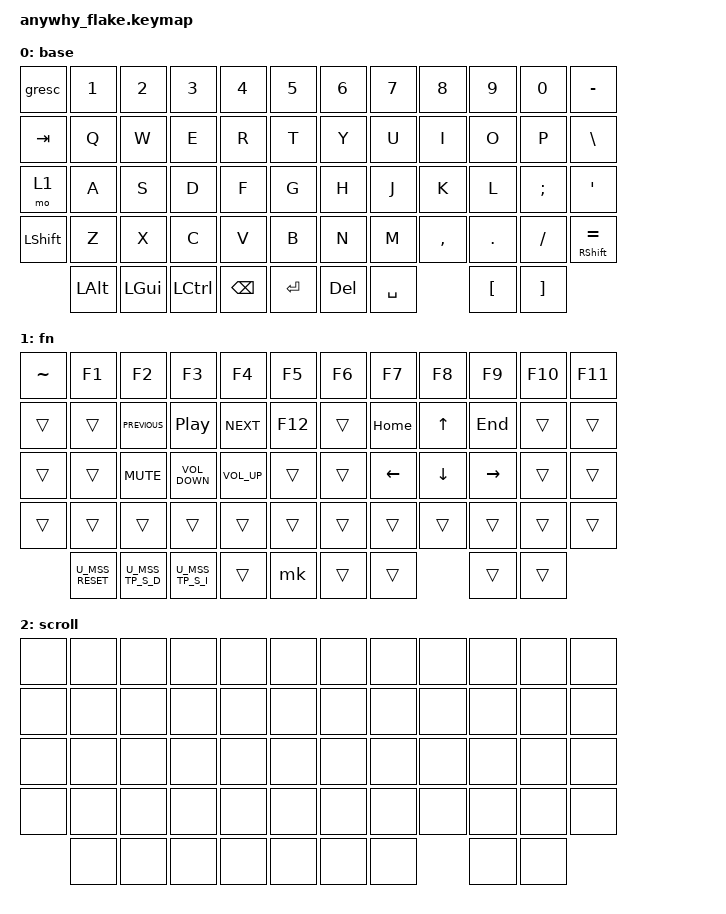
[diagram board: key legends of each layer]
#include <behaviors.dtsi>
#include <dt-bindings/zmk/mouse.h>
#include <behaviors/mouse_keys.dtsi>
#include <dt-bindings/zmk/keys.h>
#include <dt-bindings/zmk/bt.h>
#include <dt-bindings/zmk/pointing.h>

#define HAS_MOUSE_KEYS
#define HAS_MOUSE_TP

// We store the trackpoint settings in a separate file
// to make organization a little easier.
#include "include/mouse_tp.dtsi"

#define CLICK_TIMEOUT 30
#define PRIOR_IDLE 50

&mt { flavor = "tap-preferred"; };

/ {
    behaviors {
        lt: layer_tap {
            compatible = "zmk,behavior-hold-tap";
            #binding-cells = <2>;
            flavor = "tap-preferred";
            tapping-term-ms = <240>;
            quick-tap-ms = <150>;
            bindings = <&mo>, <&kp>;
        };

        mkt: layer_mouse_key_tap {
            compatible = "zmk,behavior-hold-tap";
            label = "MKT";
            #binding-cells = <2>;
            flavor = "hold-preferred";
            tapping-term-ms = <200>;
            bindings = <&mo>, <&mkp>;
        };
    };

    combos {
        compatible = "zmk,combos";

        middle_click_right {
            bindings = <&mkt 2 MCLK>;
            key-positions = <31 32 33>;
            layers = <0 1 2>;
        };

        middle_click_left {
            bindings = <&mkt 2 MCLK>;
            key-positions = <27 28 26>;
            layers = <0 1 2>;
        };

        ms-l-click {
            bindings = <&mkp LCLK>;
            key-positions = <27 28>;
            layers = <0 1 2>;
            require-prior-idle-ms = <PRIOR_IDLE>;
            timeout-ms = <CLICK_TIMEOUT>;
        };

        ms-l-click-r {
            bindings = <&mkp LCLK>;
            key-positions = <31 32>;
            layers = <0 1 2>;
            timeout-ms = <CLICK_TIMEOUT>;
            require-prior-idle-ms = <PRIOR_IDLE>;
        };

        ms-r-click {
            bindings = <&mkp RCLK>;
            key-positions = <27 26>;
            layers = <0 1 2>;
            timeout-ms = <CLICK_TIMEOUT>;
            require-prior-idle-ms = <PRIOR_IDLE>;
        };

        ms-r-click-r {
            bindings = <&mkp RCLK>;
            key-positions = <32 33>;
            layers = <0 1 2>;
            timeout-ms = <CLICK_TIMEOUT>;
            require-prior-idle-ms = <PRIOR_IDLE>;
        };

        msk_back {
            bindings = <&mkp MB4>;
            key-positions = <39 40>;
            layers = <0 1 2>;
            timeout-ms = <CLICK_TIMEOUT>;
            require-prior-idle-ms = <PRIOR_IDLE>;
        };

        msk_forward {
            bindings = <&mkp MB5>;
            key-positions = <15 16>;
            layers = <0 1 2>;
            timeout-ms = <CLICK_TIMEOUT>;
            require-prior-idle-ms = <PRIOR_IDLE>;
        };

        msk_back_r {
            bindings = <&mkp MB4>;
            key-positions = <43 44>;
            layers = <0 1 2>;
            timeout-ms = <CLICK_TIMEOUT>;
            require-prior-idle-ms = <PRIOR_IDLE>;
        };

        msk_forward_r {
            bindings = <&mkp MB5>;
            key-positions = <19 20>;
            layers = <0 1 2>;
            timeout-ms = <CLICK_TIMEOUT>;
            require-prior-idle-ms = <PRIOR_IDLE>;
        };

        msc_up {
            bindings = <&msc SCRL_UP>;
            key-positions = <14 15>;
            layers = <0 1 2>;
        };

        msc_down {
            bindings = <&msc SCRL_DOWN>;
            key-positions = <38 39>;
            layers = <0 1 2>;
        };

        shift {
            bindings = <&kp LEFT_SHIFT>;
            key-positions = <51 54>;
            layers = <0 1>;
        };
    };

    macros {
        mk: mk {
            compatible = "zmk,behavior-macro";
            #binding-cells = <0>;
            bindings = <&kp P &kp H &kp I &kp M &kp M &kp E &kp O &kp M &kp E &kp O &kp DOT &kp C &kp O &kp M>;
            label = "MK";
            wait-ms = <1>;
            tap-ms = <1>;
        };
    };

    keymap {
        compatible = "zmk,keymap";

        base {
            bindings = <
&gresc     &kp N1    &kp N2    &kp N3     &kp N4    &kp N5       &kp N6   &kp N7     &kp N8     &kp N9   &kp N0    &kp MINUS
&kp TAB    &kp Q     &kp W     &kp E      &kp R     &kp T        &kp Y    &kp U      &kp I      &kp O    &kp P     &kp BACKSLASH
&mo 1      &kp A     &kp S     &kp D      &kp F     &kp G        &kp H    &kp J      &kp K      &kp L    &kp SEMI  &kp APOS
&kp LSHFT  &kp Z     &kp X     &kp C      &kp V     &kp B        &kp N    &kp M      &kp COMMA  &kp DOT  &kp FSLH  &mt RIGHT_SHIFT EQUAL
           &kp LALT  &kp LGUI  &kp LCTRL  &kp BSPC  &kp ENTER    &kp DEL  &kp SPACE             &kp LBKT  &kp RBKT
            >;
        };

        fn {
            bindings = <
&kp TILDE  &kp F1       &kp F2          &kp F3             &kp F4           &kp F5     &kp F6   &kp F7     &kp F8     &kp F9     &kp F10   &kp F11
&trans     &trans       &kp C_PREVIOUS  &kp C_PLAY_PAUSE   &kp C_NEXT       &kp F12    &trans   &kp HOME   &kp UP     &kp END    &trans    &trans
&trans     &trans       &kp C_MUTE      &kp C_VOLUME_DOWN  &kp C_VOLUME_UP  &trans     &trans   &kp LEFT   &kp DOWN   &kp RIGHT  &trans    &trans
&trans     &trans       &trans          &trans             &trans           &trans     &trans   &trans     &trans     &trans     &trans    &trans
           U_MSS_RESET  U_MSS_TP_S_D    U_MSS_TP_S_I       &trans           &mk        &trans   &trans                &trans     &trans
            >;
        };

        scroll {
            bindings = <
&none &none &none &none &none &none    &none &none &none &none &none &none
&none &none &none &none &none &none    &none &none &none &none &none &none
&none &none &none &none &none &none    &none &none &none &none &none &none
&none &none &none &none &none &none    &none &none &none &none &none &none
      &none &none &none &none &none    &none &none       &none &none
            >;
        };
    };

};
